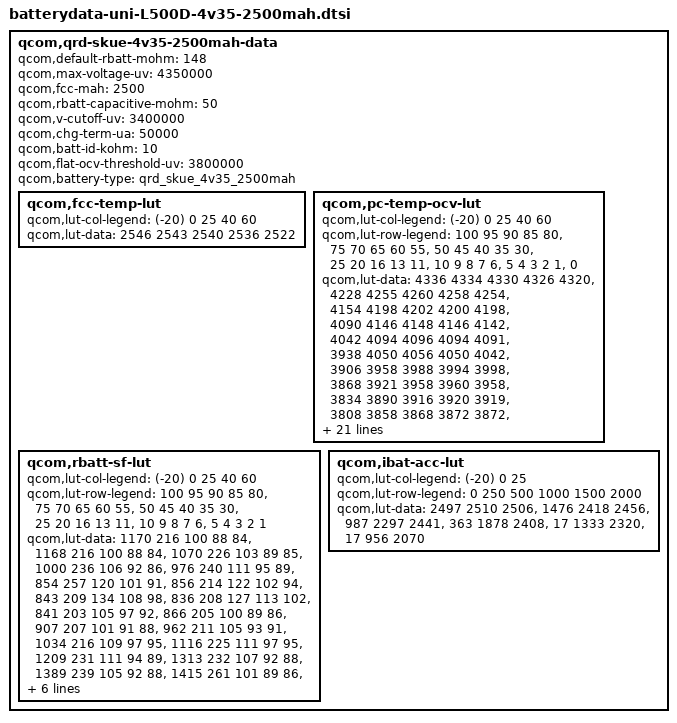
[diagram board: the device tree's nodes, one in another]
/**********uniscope-driver-modify-file-on-qualcomm-platform*****************/
/* Copyright (c) 2014, The Linux Foundation. All rights reserved.
 *
 * This program is free software; you can redistribute it and/or modify
 * it under the terms of the GNU General Public License version 2 and
 * only version 2 as published by the Free Software Foundation.
 *
 * This program is distributed in the hope that it will be useful,
 * but WITHOUT ANY WARRANTY; without even the implied warranty of
 * MERCHANTABILITY or FITNESS FOR A PARTICULAR PURPOSE.  See the
 * GNU General Public License for more details.
 */


qcom,qrd-skue-4v35-2500mah-data {
	qcom,default-rbatt-mohm = <148>;
	qcom,max-voltage-uv = <4350000>;
	qcom,fcc-mah = <2500>;
	qcom,rbatt-capacitive-mohm = <50>;
	qcom,v-cutoff-uv = <3400000>;
	qcom,chg-term-ua = <50000>;
	qcom,batt-id-kohm = <10>;
	qcom,flat-ocv-threshold-uv = <3800000>;
	qcom,battery-type = "qrd_skue_4v35_2500mah";

	qcom,fcc-temp-lut {
		qcom,lut-col-legend = <(-20) 0 25 40 60>;
		qcom,lut-data = <2546 2543 2540 2536 2522>;
	};

	qcom,pc-temp-ocv-lut {
		qcom,lut-col-legend = <(-20) 0 25 40 60>;
		qcom,lut-row-legend = <100 95 90 85 80>,
				<75 70 65 60 55>,
				<50 45 40 35 30>,
				<25 20 16 13 11>,
				<10 9 8 7 6>,
				<5 4 3 2 1>,
				<0>;
		qcom,lut-data = 
                                <4336 4334 4330 4326 4320>,
				<4228 4255 4260 4258 4254>,
				<4154 4198 4202 4200 4198>,
				<4090 4146 4148 4146 4142>,
				<4042 4094 4096 4094 4091>,
				<3938 4050 4056 4050 4042>,
				<3906 3958 3988 3994 3998>,
				<3868 3921 3958 3960 3958>,
				<3834 3890 3916 3920 3919>,
				<3808 3858 3868 3872 3872>,
				<3792 3832 3837 3838 3838>,
				<3780 3809 3814 3816 3815>,
				<3768 3790 3797 3797 3796>,
				<3757 3776 3782 3781 3780>,
				<3745 3766 3771 3768 3764>,
				<3732 3753 3761 3753 3740>,
				<3716 3732 3742 3734 3719>,
				<3696 3713 3716 3709 3696>,
				<3678 3705 3695 3687 3674>,
				<3662 3700 3690 3682 3670>,
				<3652 3697 3689 3681 3670>,
				<3638 3694 3688 3680 3669>,
				<3624 3691 3687 3679 3668>,
				<3606 3686 3685 3678 3665>,
				<3584 3676 3680 3672 3659>,
				<3556 3656 3664 3654 3636>,
				<3522 3620 3624 3612 3592>,
				<3476 3568 3564 3552 3534>,
				<3408 3490 3482 3470 3452>,
				<3289 3363 3355 3340 3322>,
				<3000 3000 3000 3000 3000>;
};

	qcom,rbatt-sf-lut {
		qcom,lut-col-legend = <(-20) 0 25 40 60>;
		qcom,lut-row-legend = <100 95 90 85 80>,
				<75 70 65 60 55>,
				<50 45 40 35 30>,
				<25 20 16 13 11>,
				<10 9 8 7 6>,
				<5 4 3 2 1>;
		qcom,lut-data = 
                                <1170 216 100 88 84>,
				<1168 216 100 88 84>,
				<1070 226 103 89 85>,
				<1000 236 106 92 86>,
				<976 240 111 95 89>,
				<854 257 120 101 91>,
				<856 214 122 102 94>,
				<843 209 134 108 98>,
				<836 208 127 113 102>,
				<841 203 105 97 92>,
				<866 205 100 89 86>,
				<907 207 101 91 88>,
				<962 211 105 93 91>,
				<1034 216 109 97 95>,
				<1116 225 111 97 95>,
				<1209 231 111 94 89>,
				<1313 232 107 92 88>,
				<1389 239 105 92 88>,
				<1415 261 101 89 86>,
				<1336 263 100 89 86>,
				<1378 274 102 91 89>,
				<1423 288 105 93 90>,
				<1469 305 109 96 91>,
				<1518 325 114 98 92>,
				<1573 345 118 99 92>,
				<1697 360 116 96 89>,
				<2001 380 111 93 90>,
				<2551 427 115 97 91>,
				<3862 499 123 103 97>,
				<7724 836 157 141 122>;
	};

	qcom,ibat-acc-lut {
		qcom,lut-col-legend = <(-20) 0 25>;
		qcom,lut-row-legend = <0 250 500 1000 1500 2000>;
		qcom,lut-data = <2497 2510 2506>,
				<1476 2418 2456>,
				<987 2297 2441>,
				<363 1878 2408>,
				<17 1333 2320>,
				<17 956 2070>;
	};
};
